# STM32L15x register map
File version: 1.0
Registers are 32-bit, read-write, reset 0x0 unless marked. A register's access mark holds for its fields unless they carry their own. Offsets are from the block's base; [hi:lo] are bit positions; {n}, {i} and the like mark numbered series.

## CRC — CRC calculation unit
Base 0x40023000
0x00 DR reset 0xFFFFFFFF — Data register
  [31:0] DR — CRC_DR
0x04 IDR — Independent data register
  [7:0] IDR
0x08 CR — Control register
  [0] RESET

## GPIOA — General-purpose I/Os
Base 0x40020000
Same registers: GPIOB 0x40020400, GPIOC 0x40020800, GPIOD 0x40020C00, GPIOE 0x40021000, GPIOF 0x40021400
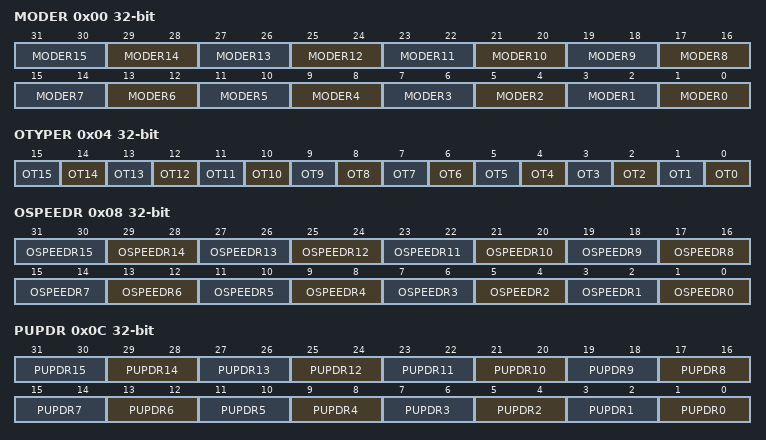
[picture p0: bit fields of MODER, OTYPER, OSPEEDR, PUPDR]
0x00 MODER — GPIO port mode register
  [2n+1:2n] MODER{n} (n=0..15)
0x04 OTYPER — GPIO port output type register
  [n] OT{n} (n=0..15)
0x08 OSPEEDR — GPIO port output speed register
  [2n+1:2n] OSPEEDR{n} (n=0..15)
0x0C PUPDR — GPIO port pull-up/pull-down register
  [2n+1:2n] PUPDR{n} (n=0..15)
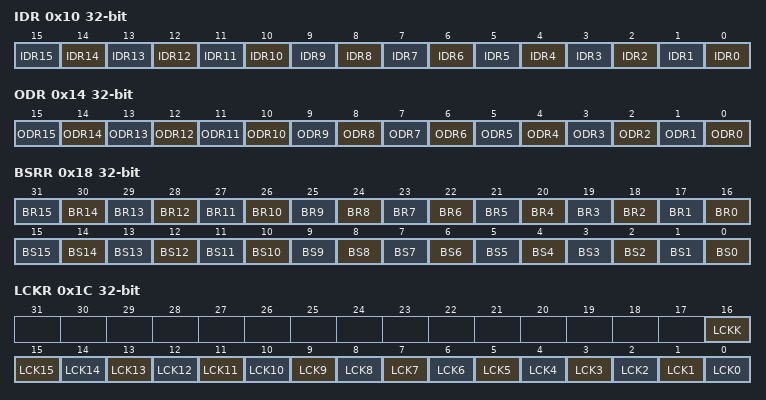
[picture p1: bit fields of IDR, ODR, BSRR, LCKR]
0x10 IDR ro — GPIO port input data register
  [n] IDR{n} (n=0..15)
0x14 ODR — GPIO port output data register
  [n] ODR{n} (n=0..15)
0x18 BSRR wo — GPIO port bit set/reset register
  [n+16] BR{n} (n=0..15), [n] BS{n} (n=0..15)
0x1C LCKR — GPIO port configuration lock register
  [16] LCKK, [n] LCK{n} (n=0..15)
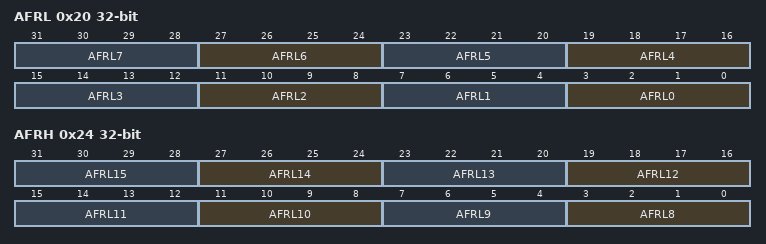
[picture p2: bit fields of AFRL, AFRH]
0x20 AFRL — GPIO alternate function low register
  [4n+3:4n] AFRL{n} (n=0..7)
0x24 AFRH — GPIO alternate function high register
  [4n-29:4n-32] AFRL{n} (n=8..15)

## USART1 — Universal synchronous asynchronous receiver
Base 0x40013800
Same registers: USART2 0x40004400, USART3 0x40004800
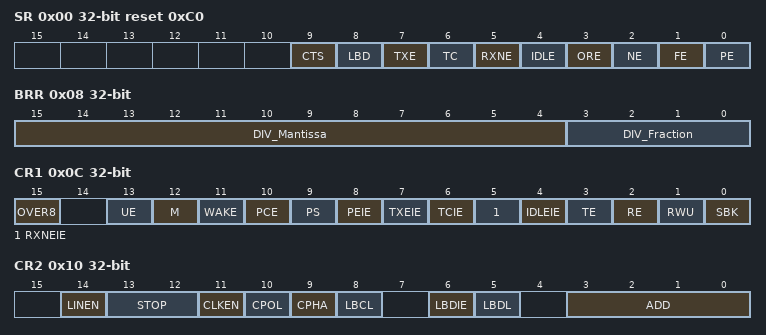
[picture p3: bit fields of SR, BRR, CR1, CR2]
0x00 SR access per field reset 0xC0 — Status register
  [9] CTS wo, [8] LBD wo, [7] TXE ro, [6] TC wo, [5] RXNE wo, [4] IDLE ro, [3] ORE ro, [2] NE ro, [1] FE ro, [0] PE ro
0x04 DR — Data register
  [8:0] DR
0x08 BRR — Baud rate register
  [15:4] DIV_Mantissa, [3:0] DIV_Fraction
0x0C CR1 — Control register 1
  [15] OVER8, [13] UE, [12] M, [11] WAKE, [10] PCE, [9] PS, [8] PEIE, [7] TXEIE, [6] TCIE, [5] RXNEIE, [4] IDLEIE, [3] TE, [2] RE, [1] RWU, [0] SBK
0x10 CR2 — Control register 2
  [14] LINEN, [13:12] STOP, [11] CLKEN, [10] CPOL, [9] CPHA, [8] LBCL, [6] LBDIE, [5] LBDL, [3:0] ADD
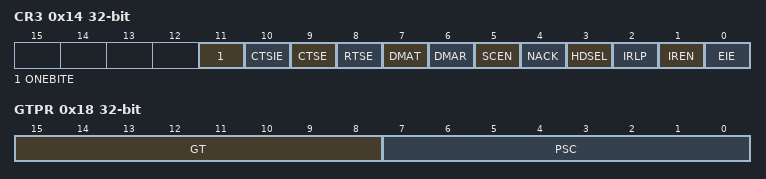
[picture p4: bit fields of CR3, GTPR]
0x14 CR3 — Control register 3
  [11] ONEBITE, [10] CTSIE, [9] CTSE, [8] RTSE, [7] DMAT, [6] DMAR, [5] SCEN, [4] NACK, [3] HDSEL, [2] IRLP, [1] IREN, [0] EIE
0x18 GTPR — Guard time and prescaler register
  [15:8] GT, [7:0] PSC

## SPI1 — Serial peripheral interface
Base 0x40013000
Same registers: SPI2 0x40003800
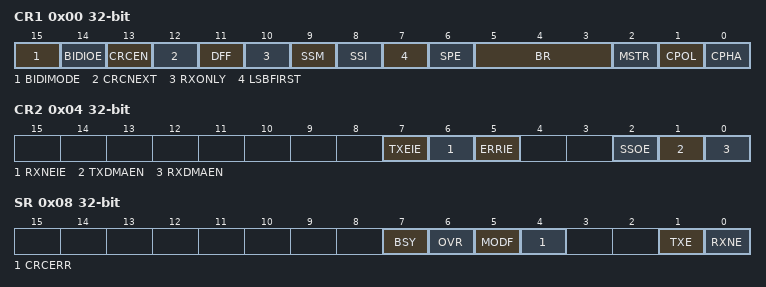
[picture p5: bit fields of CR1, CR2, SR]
0x00 CR1 — SPI control register 1
  [15] BIDIMODE, [14] BIDIOE, [13] CRCEN, [12] CRCNEXT, [11] DFF, [10] RXONLY, [9] SSM, [8] SSI, [7] LSBFIRST, [6] SPE, [5:3] BR, [2] MSTR, [1] CPOL, [0] CPHA
0x04 CR2 — SPI control register 2
  [7] TXEIE, [6] RXNEIE, [5] ERRIE, [2] SSOE, [1] TXDMAEN, [0] RXDMAEN
0x08 SR ro — SPI status register
  [7] BSY, [6] OVR, [5] MODF, [4] CRCERR, [1] TXE, [0] RXNE
0x0C DR — SPI data register
  [15:0] DR
0x10 CRCPR — SPI CRC polynomial register
  [15:0] CRCPOLY
0x14 RXCRCR ro — SPI Rx CRC register
  [15:0] RxCRC
0x18 TXCRCR ro — SPI Tx CRC register
  [15:0] TxCRC

## ADC — Analog-to-digital converter
Base 0x40012400
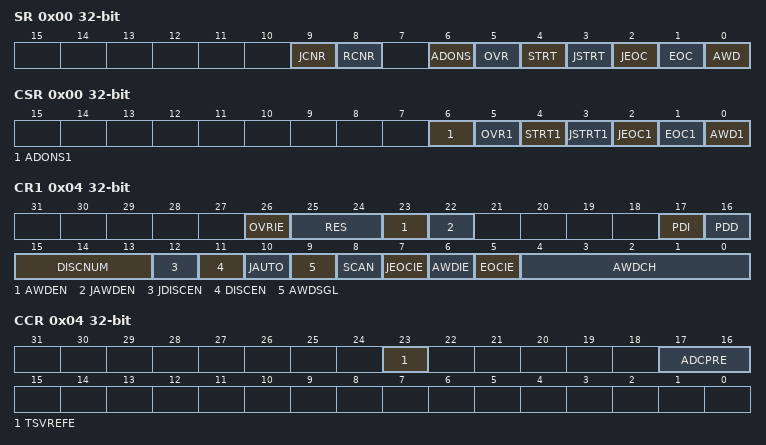
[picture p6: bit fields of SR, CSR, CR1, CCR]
0x00 SR access per field — ADC status register
  [9] JCNR ro, [8] RCNR ro, [6] ADONS ro, [5] OVR wo, [4] STRT wo, [3] JSTRT wo, [2] JEOC wo, [1] EOC wo, [0] AWD wo
0x00 CSR ro — ADC common status register
  [6] ADONS1, [5] OVR1, [4] STRT1, [3] JSTRT1, [2] JEOC1, [1] EOC1, [0] AWD1
0x04 CR1 — ADC control register 1
  [26] OVRIE, [25:24] RES, [23] AWDEN, [22] JAWDEN, [17] PDI, [16] PDD, [15:13] DISCNUM, [12] JDISCEN, [11] DISCEN, [10] JAUTO, [9] AWDSGL, [8] SCAN, [7] JEOCIE, [6] AWDIE, [5] EOCIE, [4:0] AWDCH
0x04 CCR (alternate view of CR1) — ADC common control register
  [23] TSVREFE, [17:16] ADCPRE
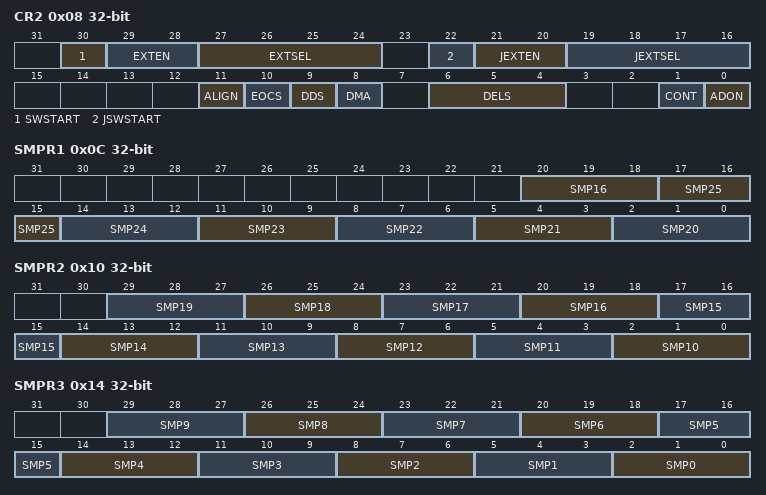
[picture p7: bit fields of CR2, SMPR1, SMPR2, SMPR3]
0x08 CR2 — ADC control register 2
  [30] SWSTART, [29:28] EXTEN, [27:24] EXTSEL, [22] JSWSTART, [21:20] JEXTEN, [19:16] JEXTSEL, [11] ALIGN, [10] EOCS, [9] DDS, [8] DMA, [6:4] DELS, [1] CONT, [0] ADON
0x0C SMPR1 — ADC sample time register 1
  [20:18] SMP16, [3n-58:3n-60] SMP{n} (n=20..25)
0x10 SMPR2 — ADC sample time register 2
  [3n-28:3n-30] SMP{n} (n=10..19)
0x14 SMPR3 — ADC sample time register 3
  [3n+2:3n] SMP{n} (n=0..9)
{0x14+4i} JOFR{i} (i=1..4) — ADC injected channel data offset register {i}
  [11:0] JOFFSET
0x28 HTR reset 0xFFF — ADC watchdog higher threshold register
  [11:0] HT
0x2C LTR — ADC watchdog lower threshold register
  [11:0] LT
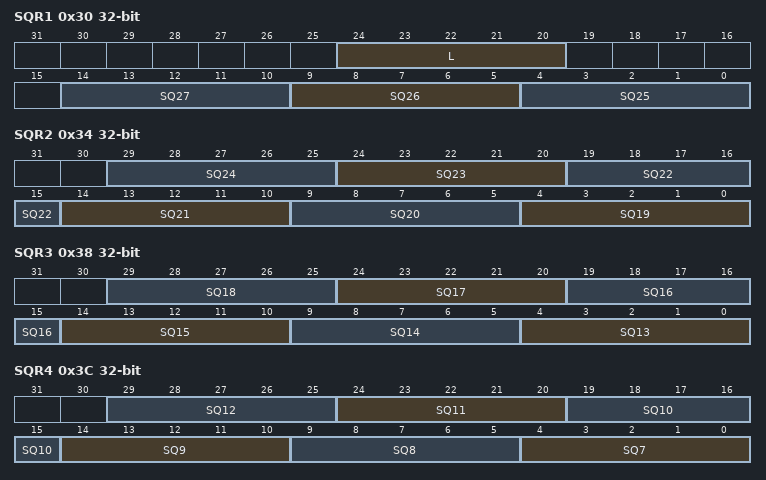
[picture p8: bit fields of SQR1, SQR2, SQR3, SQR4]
0x30 SQR1 — ADC regular sequence register 1
  [24:20] L, [14:10] SQ27, [9:5] SQ26, [4:0] SQ25
0x34 SQR2 — ADC regular sequence register 2
  [5n-91:5n-95] SQ{n} (n=19..24)
0x38 SQR3 — ADC regular sequence register 3
  [5n-61:5n-65] SQ{n} (n=13..18)
0x3C SQR4 — ADC regular sequence register 4
  [5n-31:5n-35] SQ{n} (n=7..12)
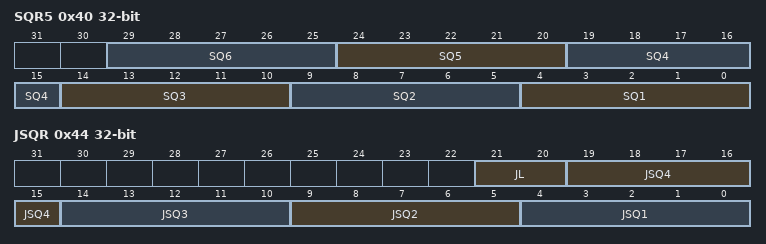
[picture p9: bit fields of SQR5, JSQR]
0x40 SQR5 — ADC regular sequence register 5
  [5n-1:5n-5] SQ{n} (n=1..6)
0x44 JSQR — ADC injected sequence register
  [21:20] JL, [5n-1:5n-5] JSQ{n} (n=1..4)
{0x44+4i} JDR{i} ro (i=1..4) — ADC injected data register {i}
  [15:0] JDATA
0x58 DR ro — ADC regular data register
  [15:0] DATA
